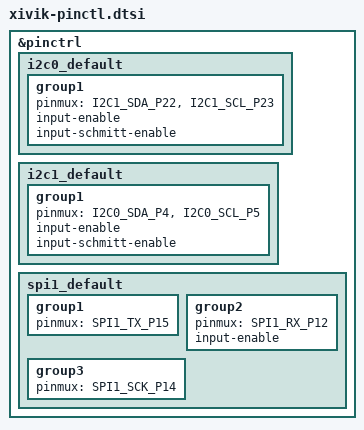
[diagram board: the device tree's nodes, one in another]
/*
 * Copyright (c) 2021, Yonatan Schachter
 * SPDX-License-Identifier: Apache-2.0
 */

#include <dt-bindings/pinctrl/rpi-pico-rp2040-pinctrl.h>

&pinctrl {
	// vik i2c pinout
	i2c0_default: i2c0_default {
		group1 {
			pinmux = <I2C1_SDA_P22>, <I2C1_SCL_P23>;
			input-enable;
			input-schmitt-enable;
		};
	};

	i2c1_default: i2c1_default {
		group1 {
			pinmux = <I2C0_SDA_P4>, <I2C0_SCL_P5>;
			input-enable;
			input-schmitt-enable;
		};
	};

	// vik spi pinout
	spi1_default: spi1_default {
		group1 {
			pinmux = <SPI1_TX_P15>;
		};
		group2 {
			pinmux = <SPI1_RX_P12>;
			input-enable;
		};
		group3 {
			pinmux = <SPI1_SCK_P14>;
		};
	};
};
